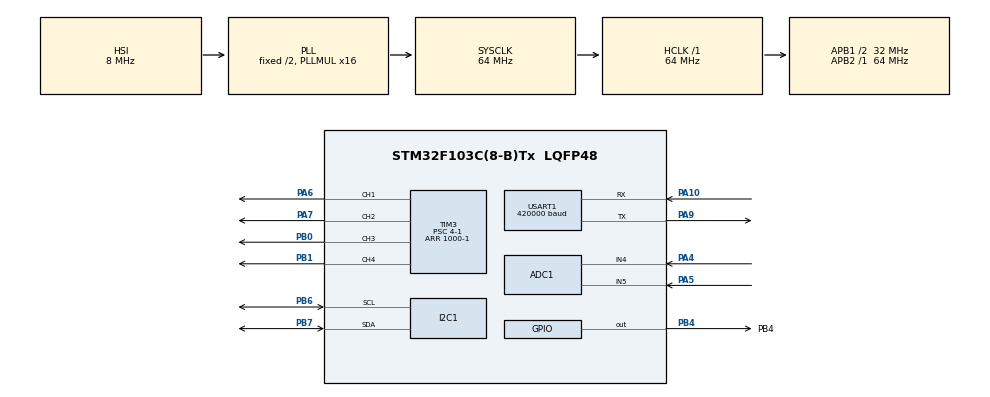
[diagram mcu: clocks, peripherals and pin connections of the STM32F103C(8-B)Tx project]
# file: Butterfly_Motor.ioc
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ADC1.Channel-0\#ChannelRegularConversion=ADC_CHANNEL_4
ADC1.Channel-1\#ChannelRegularConversion=ADC_CHANNEL_5
ADC1.Channel-2\#ChannelRegularConversion=ADC_CHANNEL_TEMPSENSOR
ADC1.Channel-3\#ChannelRegularConversion=ADC_CHANNEL_VREFINT
ADC1.ContinuousConvMode=ENABLE
ADC1.NbrOfConversion=4
ADC1.NbrOfConversionFlag=1
ADC1.Rank-0\#ChannelRegularConversion=1
ADC1.Rank-1\#ChannelRegularConversion=2
ADC1.Rank-2\#ChannelRegularConversion=3
ADC1.Rank-3\#ChannelRegularConversion=4
ADC1.SamplingTime-0\#ChannelRegularConversion=ADC_SAMPLETIME_239CYCLES_5
ADC1.SamplingTime-1\#ChannelRegularConversion=ADC_SAMPLETIME_239CYCLES_5
ADC1.SamplingTime-2\#ChannelRegularConversion=ADC_SAMPLETIME_239CYCLES_5
ADC1.SamplingTime-3\#ChannelRegularConversion=ADC_SAMPLETIME_71CYCLES_5
ADC1.master=1
Dma.ADC1.0.Direction=DMA_PERIPH_TO_MEMORY
Dma.ADC1.0.Instance=DMA1_Channel1
Dma.ADC1.0.MemDataAlignment=DMA_MDATAALIGN_HALFWORD
Dma.ADC1.0.MemInc=DMA_MINC_ENABLE
Dma.ADC1.0.Mode=DMA_CIRCULAR
Dma.ADC1.0.PeriphDataAlignment=DMA_PDATAALIGN_HALFWORD
Dma.ADC1.0.PeriphInc=DMA_PINC_DISABLE
Dma.ADC1.0.Priority=DMA_PRIORITY_LOW
Dma.Request0=ADC1
Dma.Request1=USART1_RX
Dma.USART1_RX.1.Direction=DMA_PERIPH_TO_MEMORY
Dma.USART1_RX.1.Instance=DMA1_Channel5
Dma.USART1_RX.1.MemDataAlignment=DMA_MDATAALIGN_BYTE
Dma.USART1_RX.1.MemInc=DMA_MINC_ENABLE
Dma.USART1_RX.1.Mode=DMA_NORMAL
Dma.USART1_RX.1.PeriphDataAlignment=DMA_PDATAALIGN_BYTE
Dma.USART1_RX.1.PeriphInc=DMA_PINC_DISABLE
Dma.USART1_RX.1.Priority=DMA_PRIORITY_LOW
FREERTOS.Tasks01=defaultTask,24,128,StartDefaultTask,Default,NULL,Dynamic,NULL,NULL
Mcu.Family=STM32F1
Mcu.Name=STM32F103C(8-B)Tx
Mcu.Package=LQFP48
NVIC.ADC1_2_IRQn=true\:5\:0\:false\:false\:true\:true\:true\:true\:true
NVIC.DMA1_Channel1_IRQn=true\:5\:0\:false\:false\:true\:true\:false\:true\:true
NVIC.DMA1_Channel5_IRQn=true\:5\:0\:false\:false\:true\:true\:false\:true\:true
NVIC.PriorityGroup=NVIC_PRIORITYGROUP_4
NVIC.TIM4_IRQn=true\:15\:0\:false\:false\:true\:false\:false\:true\:true
NVIC.TimeBase=TIM4_IRQn
NVIC.TimeBaseIP=TIM4
NVIC.USART1_IRQn=true\:5\:0\:false\:false\:true\:true\:true\:true\:true
PA10.Mode=Asynchronous
PA10.Signal=USART1_RX
PA13.Mode=Serial_Wire
PA13.Signal=SYS_JTMS-SWDIO
PA14.Mode=Serial_Wire
PA14.Signal=SYS_JTCK-SWCLK
PA4.Signal=ADCx_IN4
PA5.Signal=ADCx_IN5
PA6.Signal=S_TIM3_CH1
PA7.Signal=S_TIM3_CH2
PA9.Mode=Asynchronous
PA9.Signal=USART1_TX
PB0.Signal=S_TIM3_CH3
PB1.Signal=S_TIM3_CH4
PB4.GPIO_Label=PB4
PB4.Signal=GPIO_Output
PB6.Mode=I2C
PB6.Signal=I2C1_SCL
PB7.Mode=I2C
PB7.Signal=I2C1_SDA
ProjectManager.HeapSize=0x200
ProjectManager.StackSize=0x400
ProjectManager.TargetToolchain=CMake
RCC.ADCPresc=RCC_ADCPCLK2_DIV6
RCC.AHBFreq_Value=64000000
RCC.APB1CLKDivider=RCC_HCLK_DIV2
RCC.APB1Freq_Value=32000000
RCC.APB1TimFreq_Value=64000000
RCC.APB2Freq_Value=64000000
RCC.APB2TimFreq_Value=64000000
RCC.HCLKFreq_Value=64000000
RCC.PLLMUL=RCC_PLL_MUL16
RCC.SYSCLKFreq_VALUE=64000000
RCC.SYSCLKSource=RCC_SYSCLKSOURCE_PLLCLK
RCC.USBFreq_Value=64000000
SH.ADCx_IN4.0=ADC1_IN4,IN4
SH.ADCx_IN5.0=ADC1_IN5,IN5
SH.S_TIM3_CH1.0=TIM3_CH1,PWM Generation1 CH1
SH.S_TIM3_CH2.0=TIM3_CH2,PWM Generation2 CH2
SH.S_TIM3_CH3.0=TIM3_CH3,PWM Generation3 CH3
SH.S_TIM3_CH4.0=TIM3_CH4,PWM Generation4 CH4
STMicroelectronics.X-CUBE-ALGOBUILD.1.4.0.LibraryCcDSPOoLibraryJjDSPOoLibrary=true
TIM3.Channel-PWM\ Generation1\ CH1=TIM_CHANNEL_1
TIM3.Channel-PWM\ Generation2\ CH2=TIM_CHANNEL_2
TIM3.Channel-PWM\ Generation3\ CH3=TIM_CHANNEL_3
TIM3.Channel-PWM\ Generation4\ CH4=TIM_CHANNEL_4
TIM3.Period=1000-1
TIM3.Prescaler=4-1
USART1.BaudRate=420000
USART1.VirtualMode=VM_ASYNC
VP_ADC1_TempSens_Input.Mode=IN-TempSens
VP_ADC1_Vref_Input.Mode=IN-Vrefint
VP_FREERTOS_VS_CMSIS_V2.Mode=CMSIS_V2
VP_STMicroelectronics.X-CUBE-ALGOBUILD_VS_DSPOoLibraryJjLibrary_1.4.0_1.4.0.Mode=DSPOoLibraryJjLibrary
VP_SYS_VS_tim4.Mode=TIM4
board=custom

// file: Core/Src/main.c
/* USER CODE BEGIN Header */
/**
  ******************************************************************************
  * @file           : main.c
  * @brief          : Main program body
  ******************************************************************************
  * @attention
  *
  * Copyright (c) 2026 STMicroelectronics.
  * All rights reserved.
  *
  * This software is licensed under terms that can be found in the LICENSE file
  * in the root directory of this software component.
  * If no LICENSE file comes with this software, it is provided AS-IS.
  *
  ******************************************************************************
  */
/* USER CODE END Header */
#include "main.h"
#include "cmsis_os.h"
#include "adc.h"
#include "dma.h"
#include "i2c.h"
#include "tim.h"
#include "usart.h"
#include "gpio.h"

/* USER CODE BEGIN Includes */
#include "butterfly.h"
/* USER CODE END Includes */

void SystemClock_Config(void);
void MX_FREERTOS_Init(void);

int main(void)
{

  /* MCU Configuration--------------------------------------------------------*/

  /* Reset of all peripherals, Initializes the Flash interface and the Systick. */
  HAL_Init();

  /* Configure the system clock */
  SystemClock_Config();

  /* Initialize all configured peripherals */
  MX_GPIO_Init();
  MX_DMA_Init();
  MX_ADC1_Init();
  MX_TIM3_Init();
  MX_USART1_UART_Init();
  MX_I2C1_Init();
  /* USER CODE BEGIN 2 */
  Butterfly_Init();

  /* USER CODE END 2 */

  /* Init scheduler */
  osKernelInitialize();  /* Call init function for freertos objects (in cmsis_os2.c) */
  MX_FREERTOS_Init();

  /* Start scheduler */
  osKernelStart();

  /* We should never get here as control is now taken by the scheduler */

  /* Infinite loop */
  while (1)
  {

  }
}

void SystemClock_Config(void)
{
  RCC_OscInitTypeDef RCC_OscInitStruct = {0};
  RCC_ClkInitTypeDef RCC_ClkInitStruct = {0};
  RCC_PeriphCLKInitTypeDef PeriphClkInit = {0};

  /** Initializes the RCC Oscillators according to the specified parameters
  * in the RCC_OscInitTypeDef structure.
  */
  RCC_OscInitStruct.OscillatorType = RCC_OSCILLATORTYPE_HSI;
  RCC_OscInitStruct.HSIState = RCC_HSI_ON;
  RCC_OscInitStruct.HSICalibrationValue = RCC_HSICALIBRATION_DEFAULT;
  RCC_OscInitStruct.PLL.PLLState = RCC_PLL_ON;
  RCC_OscInitStruct.PLL.PLLSource = RCC_PLLSOURCE_HSI_DIV2;
  RCC_OscInitStruct.PLL.PLLMUL = RCC_PLL_MUL16;
  if (HAL_RCC_OscConfig(&RCC_OscInitStruct) != HAL_OK)
  {
    Error_Handler();
  }

  /** Initializes the CPU, AHB and APB buses clocks
  */
  RCC_ClkInitStruct.ClockType = RCC_CLOCKTYPE_HCLK|RCC_CLOCKTYPE_SYSCLK
                              |RCC_CLOCKTYPE_PCLK1|RCC_CLOCKTYPE_PCLK2;
  RCC_ClkInitStruct.SYSCLKSource = RCC_SYSCLKSOURCE_PLLCLK;
  RCC_ClkInitStruct.AHBCLKDivider = RCC_SYSCLK_DIV1;
  RCC_ClkInitStruct.APB1CLKDivider = RCC_HCLK_DIV2;
  RCC_ClkInitStruct.APB2CLKDivider = RCC_HCLK_DIV1;

  if (HAL_RCC_ClockConfig(&RCC_ClkInitStruct, FLASH_LATENCY_2) != HAL_OK)
  {
    Error_Handler();
  }
  PeriphClkInit.PeriphClockSelection = RCC_PERIPHCLK_ADC;
  PeriphClkInit.AdcClockSelection = RCC_ADCPCLK2_DIV6;
  if (HAL_RCCEx_PeriphCLKConfig(&PeriphClkInit) != HAL_OK)
  {
    Error_Handler();
  }
}

void HAL_TIM_PeriodElapsedCallback(TIM_HandleTypeDef *htim)
{
  if (htim->Instance == TIM4)
  {
    HAL_IncTick();
  }
}

void Error_Handler(void)
{
  __disable_irq();
  while (1)
  {
  }
}

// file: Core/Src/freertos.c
/* USER CODE BEGIN Header */
/**
  ******************************************************************************
  * File Name          : freertos.c
  * Description        : Code for freertos applications
  ******************************************************************************
  * @attention
  *
  * Copyright (c) 2026 STMicroelectronics.
  * All rights reserved.
  *
  * This software is licensed under terms that can be found in the LICENSE file
  * in the root directory of this software component.
  * If no LICENSE file comes with this software, it is provided AS-IS.
  *
  ******************************************************************************
  */
/* USER CODE END Header */

#include "FreeRTOS.h"
#include "task.h"
#include "main.h"
#include "cmsis_os.h"

/* Definitions for defaultTask */
osThreadId_t defaultTaskHandle;
const osThreadAttr_t defaultTask_attributes = {
  .name = "defaultTask",
  .stack_size = 128 * 4,
  .priority = (osPriority_t) osPriorityNormal,
};

void StartDefaultTask(void *argument);

void MX_FREERTOS_Init(void); /* (MISRA C 2004 rule 8.1) */

void MX_FREERTOS_Init(void) {

  /* Create the thread(s) */
  /* creation of defaultTask */
  defaultTaskHandle = osThreadNew(StartDefaultTask, NULL, &defaultTask_attributes);

}

void StartDefaultTask(void *argument)
{
  /* USER CODE BEGIN StartDefaultTask */
  /* Infinite loop */
  for(;;)
  {
    HAL_GPIO_TogglePin(PB4_GPIO_Port, PB4_Pin);
    osDelay(1000);
  }
  /* USER CODE END StartDefaultTask */
}
